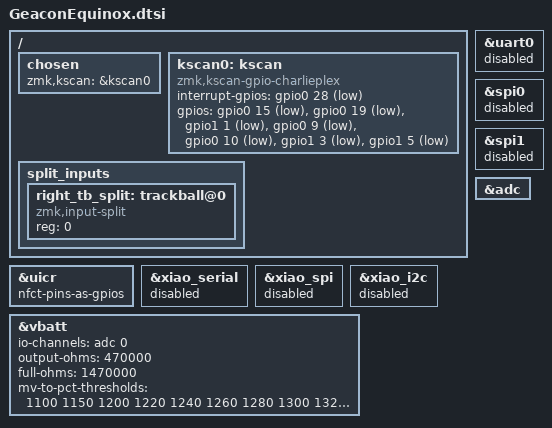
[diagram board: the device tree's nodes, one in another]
#include <dt-bindings/gpio/gpio.h>
#include <dt-bindings/pinctrl/nrf-pinctrl.h>
#include <dt-bindings/zmk/matrix_transform.h>
#include <dt-bindings/zmk/input_transform.h>
#include <zephyr/dt-bindings/input/input-event-codes.h>
#include <input/processors.dtsi>
#include "GeaconEquinox_led.dtsi"
/ {
    chosen { zmk,kscan = &kscan0; };
    kscan0: kscan {
        compatible = "zmk,kscan-gpio-charlieplex";
        interrupt-gpios = <&gpio0 28 GPIO_ACTIVE_LOW>;
        /* S0..S6: EasyEDA GeaconSolstice3, U103 pins 15..22. */
        gpios = <&gpio0 15 GPIO_ACTIVE_LOW>, <&gpio0 19 GPIO_ACTIVE_LOW>,
                <&gpio1 1 GPIO_ACTIVE_LOW>, <&gpio0 9 GPIO_ACTIVE_LOW>,
                <&gpio0 10 GPIO_ACTIVE_LOW>, <&gpio1 3 GPIO_ACTIVE_LOW>,
                <&gpio1 5 GPIO_ACTIVE_LOW>;
    };
    split_inputs {
        #address-cells = <1>;
        #size-cells = <0>;
        right_tb_split: trackball@0 {
            compatible = "zmk,input-split";
            reg = <0>;
        };
    };
};
&uicr { nfct-pins-as-gpios; };
&uart0 { status = "disabled"; };
&xiao_serial { status = "disabled"; };
&xiao_spi { status = "disabled"; };
&xiao_i2c { status = "disabled"; };
&spi0 { status = "disabled"; };
&spi1 { status = "disabled"; };

/* External NiMH Bat board, identical to Polaris: D0 / P0.02 / AIN0.
 * Override XIAO's onboard LiPo divider and its switched measurement pin. */
&vbatt {
    io-channels = <&adc 0>;
    /delete-property/ power-gpios;
    output-ohms = <470000>;
    full-ohms = <1470000>;
    mv-to-pct-thresholds = <1100 1150 1200 1220 1240 1260 1280 1300 1320 1350 1400>;
};
&adc { status = "okay"; };
